# STM32C532 register map
File version: 2.1.0
CPU: CM33 r0p4, little endian, MPU, FPU, 4 interrupt priority bits
Registers are 32-bit, read-write, reset 0x0 unless marked. A register's access mark holds for its fields unless they carry their own. Offsets are from the block's base; [hi:lo] are bit positions; 'fields as' and 'values as' point back to an identical list.

## ADCC12 — ADCC12 address block description
Base 0x42028300
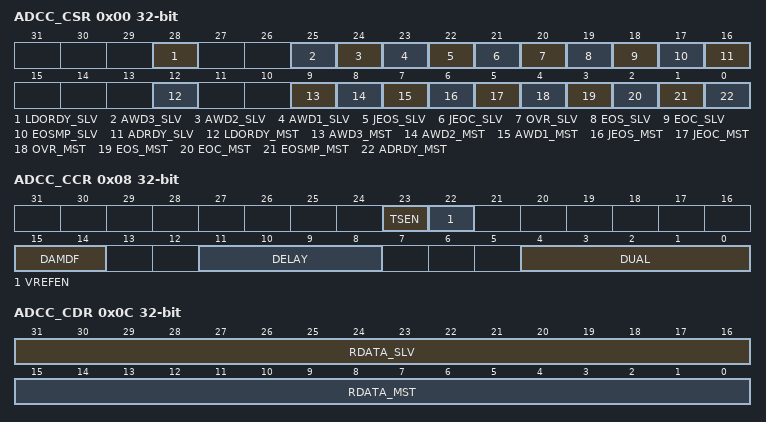
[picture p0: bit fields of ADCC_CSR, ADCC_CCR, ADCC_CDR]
0x00 ADCC_CSR ro — ADC common status register
  [28] LDORDY_SLV — ADC internal voltage regulator flag of the slave ADC
  [25] AWD3_SLV — Analog watchdog 3 flag of the slave ADC
  [24] AWD2_SLV — Analog watchdog 2 flag of the slave ADC
  [23] AWD1_SLV — Analog watchdog 1 flag of the slave ADC
  [22] JEOS_SLV — End of injected sequence flag of the slave ADC
  [21] JEOC_SLV — End of injected conversion flag of the slave ADC
  [20] OVR_SLV — Overrun flag of the slave ADC
  [19] EOS_SLV — End of regular sequence flag of the slave ADC.
  [18] EOC_SLV — End of regular conversion of the slave ADC
  [17] EOSMP_SLV — End of sampling phase flag of the slave ADC
  [16] ADRDY_SLV — Slave ADC ready
  [12] LDORDY_MST — ADC internal voltage regulator flag of the master ADC
  [9] AWD3_MST — Analog watchdog 3 flag of the master ADC
  [8] AWD2_MST — Analog watchdog 2 flag of the master ADC
  [7] AWD1_MST — Analog watchdog 1 flag of the master ADC
  [6] JEOS_MST — End of injected sequence flag of the master ADC
  [5] JEOC_MST — End of injected conversion flag of the master ADC
  [4] OVR_MST — Overrun flag of the master ADC
  [3] EOS_MST — End of regular sequence flag of the master ADC
  [2] EOC_MST — End of regular conversion of the master ADC
  [1] EOSMP_MST — End of Sampling phase flag of the master ADC
  [0] ADRDY_MST — Master ADC ready
0x08 ADCC_CCR — ADC common control register
  [23] TSEN — Temperature sensor voltage enable
    0=Temperature sensor channel disabled; 1=Temperature sensor channel enabled
  [22] VREFEN — Vless thansub>REFINTless than/sub> enable
    0=Vless thansub>REFINTless than/sub> channel disabled; 1=Vless thansub>REFINTless than/sub> channel enabled
  [15:14] DAMDF — Dual ADC mode data format
    0=Dual ADC mode without data packing (ADCC_CDR and ADCC_CDR2 registers not used); 2=Data formatting mode for any data width (ADCC_CDR data register is used when the data width is less than 16 bits, otherwise ADCC_CDR2 register is used); 3=Data formatting mode for data width lower that 8 bits (ADCC_CDR data register is used)
  [11:8] DELAY — Delay between two sampling phases
  [4:0] DUAL — Dual ADC mode selection
    0=Independent mode; 1=Combined regular simultaneous + Injected simultaneous mode; 2=Combined regular simultaneous + Alternate trigger mode; 3=Combined interleaved mode + Injected simultaneous mode; 5=Injected simultaneous mode only; 6=Regular simultaneous mode only; 7=Interleaved mode only; 9=Alternate trigger mode only
0x0C ADCC_CDR ro — ADC common regular data register for dual mode
  [31:16] RDATA_SLV — Regular data of the slave ADC
  [15:0] RDATA_MST — Regular data of the master ADC.
0x10 ADCC_CDR2 ro — ADC common regular data register for dual mode
  [31:0] RDATA_ALT — Regular data of the master/slave alternated ADCs.

## COMP12 — COMP register block
Base 0x40004000
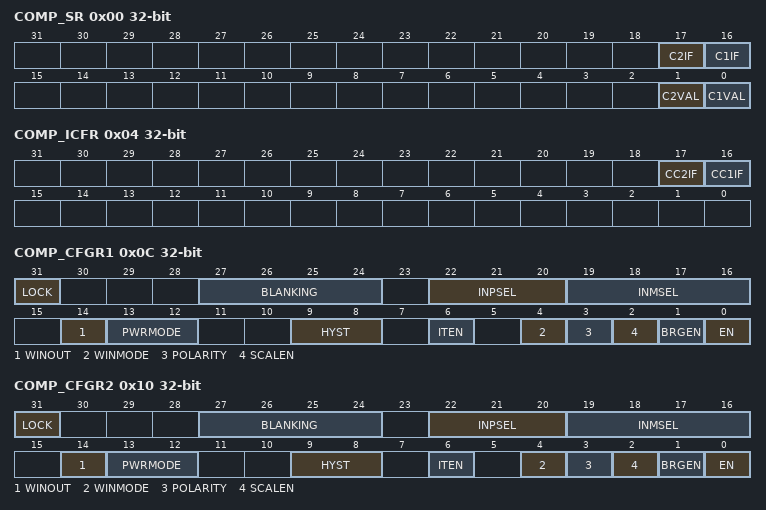
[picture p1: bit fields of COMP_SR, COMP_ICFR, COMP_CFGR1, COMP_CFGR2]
0x00 COMP_SR ro — Comparator status register
  [17] C2IF — COMP2 channel interrupt flag
  [16] C1IF — COMP1 channel interrupt flag
  [1] C2VAL — COMP2 channel output status bit
  [0] C1VAL — COMP1 channel output status bit
0x04 COMP_ICFR — Comparator interrupt clear flag register
  [17] CC2IF — Clear COMP2 channel interrupt flag
  [16] CC1IF — Clear COMP1 channel interrupt flag
0x0C COMP_CFGR1 — Comparator configuration register 1
  [31] LOCK
    0=COMP_CFGR1[31:0] register is read/write; 1=COMP_CFGR1[31:0] is read-only
  [27:24] BLANKING — COMP1 channel blanking source selection
  [22:20] INPSEL — COMP1 non-inverting input selection
  [19:16] INMSEL — COMP1 channel inverting input selection
  [14] WINOUT — COMP1 output selector
    0=COMP1_VALUE; 1=COMP1_VALUE XOR COMP2_VALUE (required for window mode, see Figure152: Window comparators functional block diagram
  [13:12] PWRMODE — Power mode of the COMP1 channel
    0=High speed/high power; 1=Medium speed/medium power
  [9:8] HYST — COMP channel hysteresis selection
    0=No hysteresis; 1=Low hysteresis; 2=Medium hysteresis; 3=High hysteresis
  [6] ITEN — COMP channel interrupt enable
    0=Interrupt generation disabled for COMP channel; 1=Interrupt generation enabled for COMP channel
  [4] WINMODE — COMP1 non-inverting input selector for window mode
    0=Signal selected with INPSEL[1:0]; 1=COMP2_INP signal of COMP2 (required for window mode, see Figure152: Window comparators functional block diagram
  [3] POLARITY — COMP channel polarity selection
    0=COMP channel output is not inverted; 1=COMP channel output is inverted
  [2] SCALEN — Voltage scaler enable
    0=Vless thansub>REFINTless than/sub> scaler disabled; 1=Vless thansub>REFINTless than/sub> scaler enabled
  [1] BRGEN — Scaler bridge enable
    0=Scaler resistor bridge disabled; 1=Scaler resistor bridge enabled
  [0] EN — COMP channel enable
    0=Disable; 1=Enable
0x10 COMP_CFGR2 — Comparator configuration register 2
  [31] LOCK
    0=COMP_CFGR2[31:0] register is read/write; 1=COMP_CFGR2[31:0] is read-only
  [27:24] BLANKING — COMP2 channel blanking source selection
  [22:20] INPSEL — COMP2 non-inverting input selection
  [19:16] INMSEL — COMP2 channel inverting input selection
  [14] WINOUT — COMP2 output selector
    0=COMP2_VALUE; 1=COMP1_VALUE XOR COMP2_VALUE (required for window mode, see Figure152: Window comparators functional block diagram
  [13:12] PWRMODE — Power mode of the COMP2 channel
    0=High speed/high power; 1=Medium speed/medium power
  [9:8] HYST — COMP channel hysteresis selection
    values as COMP_CFGR1.HYST
  [6] ITEN — COMP channel interrupt enable
    values as COMP_CFGR1.ITEN
  [4] WINMODE — COMP2 non-inverting input selector for window mode
    values as COMP_CFGR1.WINMODE
  [3] POLARITY — COMP channel polarity selection
    values as COMP_CFGR1.POLARITY
  [2] SCALEN — Voltage scaler enable
    values as COMP_CFGR1.SCALEN
  [1] BRGEN — Scaler bridge enable
    values as COMP_CFGR1.BRGEN
  [0] EN — COMP channel enable
    0=Disable; 1=Enable

## Notices in the file
Copyright (c) 2026 STMicroelectronics.
SPDX-License-Identifier: Apache-2.0
Licensed under the Apache License, Version 2.0 (the "License");
you may not use this file except in compliance with the License.
You may obtain a copy of the License at
http://www.apache.org/licenses/LICENSE-2.0
Unless required by applicable law or agreed to in writing, software
distributed under the License is distributed on an "AS IS" BASIS,
WITHOUT WARRANTIES OR CONDITIONS OF ANY KIND, either express or implied.
See the License for the specific language governing permissions and
limitations under the License.
